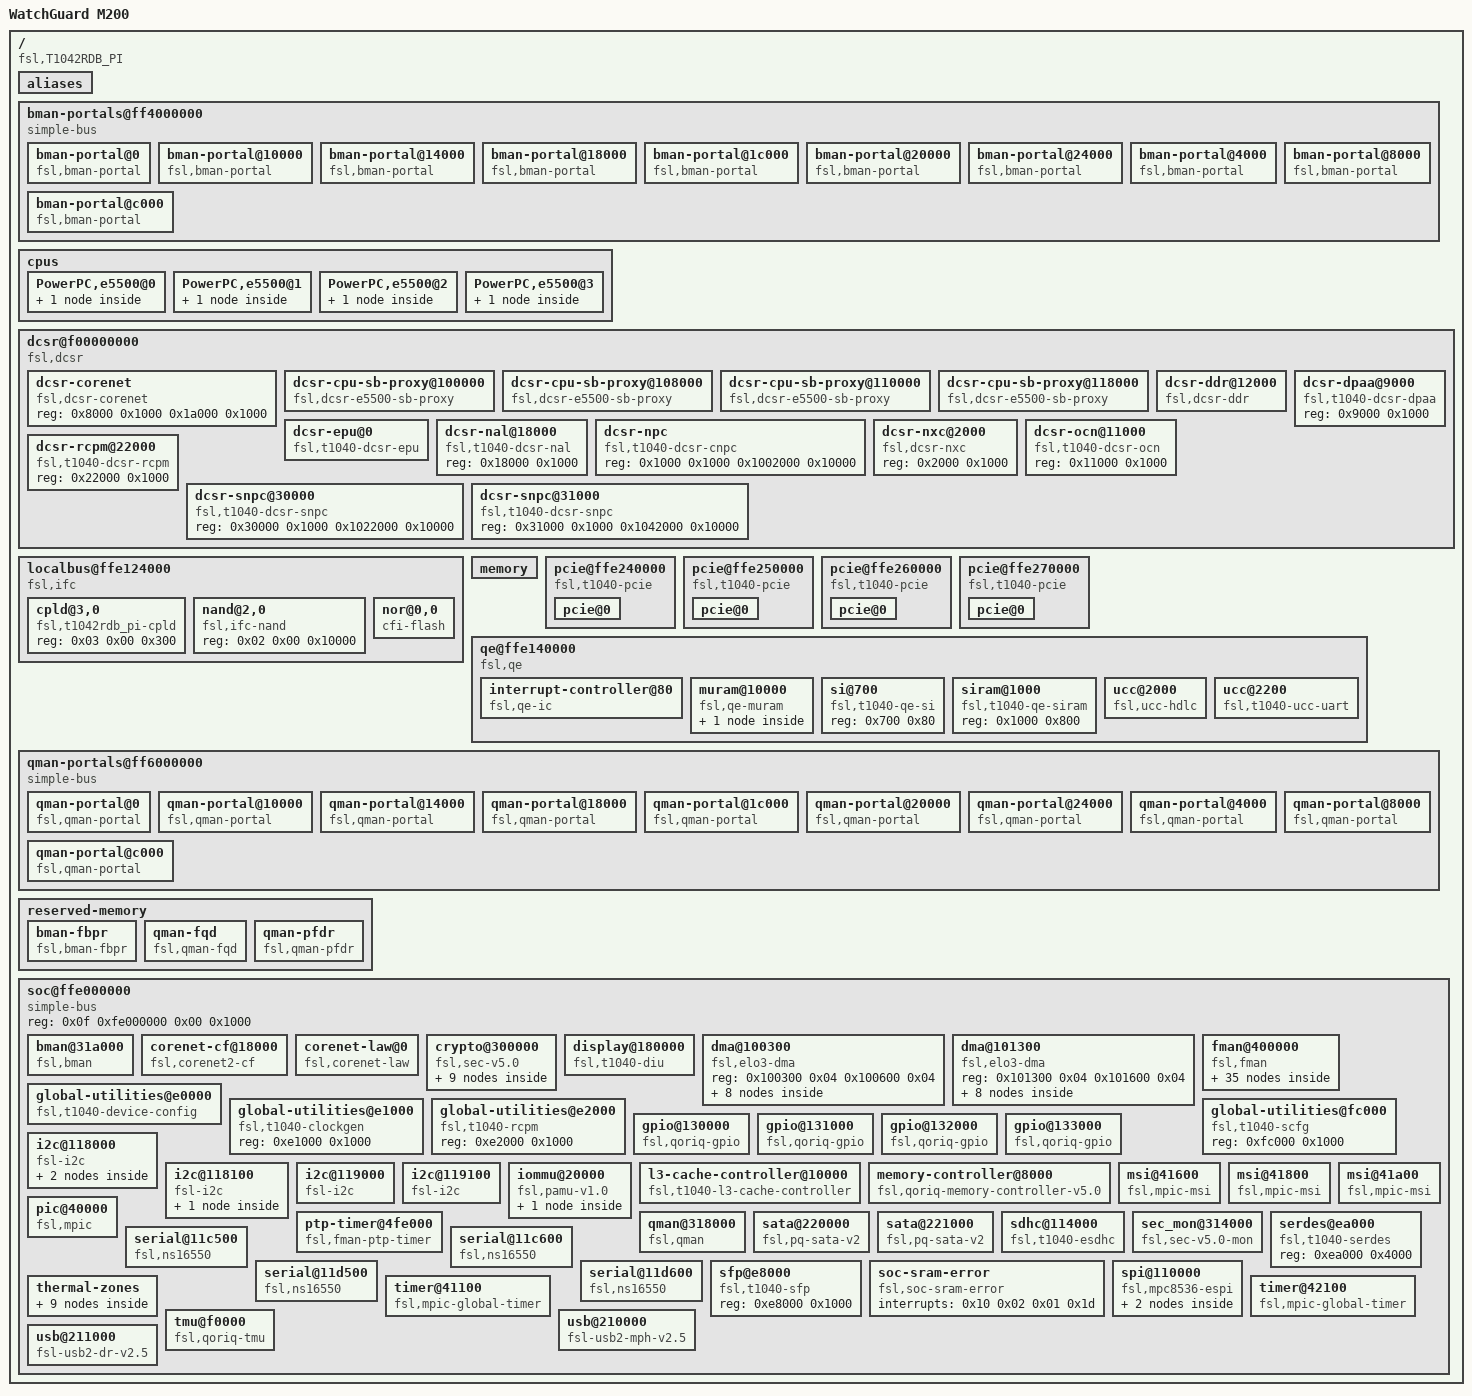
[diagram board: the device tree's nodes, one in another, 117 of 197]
/dts-v1/;

/ {
	#address-cells = <0x02>;
	#size-cells = <0x02>;
	compatible = "fsl,T1042RDB_PI";
	interrupt-parent = <0x01>;
	model = "WatchGuard M200";

	aliases {
		ccsr = "/soc@ffe000000";
		crypto = "/soc@ffe000000/crypto@300000";
		dcsr = "/dcsr@f00000000";
		ethernet0 = "/soc@ffe000000/fman@400000/ethernet@e0000";
		ethernet1 = "/soc@ffe000000/fman@400000/ethernet@e2000";
		ethernet2 = "/soc@ffe000000/fman@400000/ethernet@e4000";
		ethernet3 = "/soc@ffe000000/fman@400000/ethernet@e6000";
		ethernet4 = "/soc@ffe000000/fman@400000/ethernet@e8000";
		fman0 = "/soc@ffe000000/fman@400000";
		pci0 = "/pcie@ffe240000";
		pci1 = "/pcie@ffe250000";
		pci2 = "/pcie@ffe260000";
		pci3 = "/pcie@ffe270000";
		phy_rgmii_0 = "/soc@ffe000000/fman@400000/mdio@fc000/ethernet-phy@1";
		phy_rgmii_1 = "/soc@ffe000000/fman@400000/mdio@fc000/ethernet-phy@2";
		phy_sgmii_2 = "/soc@ffe000000/fman@400000/mdio@fc000/ethernet-phy@3";
		sdhc = "/soc@ffe000000/sdhc@114000";
		serial0 = "/soc@ffe000000/serial@11c500";
		serial1 = "/soc@ffe000000/serial@11c600";
		serial2 = "/soc@ffe000000/serial@11d500";
		serial3 = "/soc@ffe000000/serial@11d600";
		usb0 = "/soc@ffe000000/usb@210000";
		usb1 = "/soc@ffe000000/usb@211000";
	};

	bman-portals@ff4000000 {
		#address-cells = <0x01>;
		#size-cells = <0x01>;
		compatible = "simple-bus";
		phandle = <0x26>;
		ranges = <0x00 0x0f 0xf4000000 0x2000000>;

		bman-portal@0 {
			compatible = "fsl,bman-portal";
			interrupts = <0x69 0x02 0x00 0x00>;
			reg = <0x00 0x4000 0x1000000 0x1000>;
		};

		bman-portal@10000 {
			compatible = "fsl,bman-portal";
			interrupts = <0x71 0x02 0x00 0x00>;
			reg = <0x10000 0x4000 0x1004000 0x1000>;
		};

		bman-portal@14000 {
			compatible = "fsl,bman-portal";
			interrupts = <0x73 0x02 0x00 0x00>;
			reg = <0x14000 0x4000 0x1005000 0x1000>;
		};

		bman-portal@18000 {
			compatible = "fsl,bman-portal";
			interrupts = <0x75 0x02 0x00 0x00>;
			reg = <0x18000 0x4000 0x1006000 0x1000>;
		};

		bman-portal@1c000 {
			compatible = "fsl,bman-portal";
			interrupts = <0x77 0x02 0x00 0x00>;
			reg = <0x1c000 0x4000 0x1007000 0x1000>;
		};

		bman-portal@20000 {
			compatible = "fsl,bman-portal";
			interrupts = <0x79 0x02 0x00 0x00>;
			reg = <0x20000 0x4000 0x1008000 0x1000>;
		};

		bman-portal@24000 {
			compatible = "fsl,bman-portal";
			interrupts = <0x7b 0x02 0x00 0x00>;
			reg = <0x24000 0x4000 0x1009000 0x1000>;
		};

		bman-portal@4000 {
			compatible = "fsl,bman-portal";
			interrupts = <0x6b 0x02 0x00 0x00>;
			reg = <0x4000 0x4000 0x1001000 0x1000>;
		};

		bman-portal@8000 {
			compatible = "fsl,bman-portal";
			interrupts = <0x6d 0x02 0x00 0x00>;
			reg = <0x8000 0x4000 0x1002000 0x1000>;
		};

		bman-portal@c000 {
			compatible = "fsl,bman-portal";
			interrupts = <0x6f 0x02 0x00 0x00>;
			reg = <0xc000 0x4000 0x1003000 0x1000>;
		};
	};

	cpus {
		#address-cells = <0x01>;
		#size-cells = <0x00>;
		fsl,eref-deo;
		mmu-type = "power-embedded";
		power-isa-64;
		power-isa-atb;
		power-isa-b;
		power-isa-cs;
		power-isa-ds;
		power-isa-e;
		power-isa-e.ed;
		power-isa-e.hv;
		power-isa-e.le;
		power-isa-e.pc;
		power-isa-e.pd;
		power-isa-e.pm;
		power-isa-ecl;
		power-isa-exp;
		power-isa-fp;
		power-isa-fp.r;
		power-isa-mmc;
		power-isa-scpm;
		power-isa-version = "2.06";
		power-isa-wt;

		PowerPC,e5500@0 {
			#cooling-cells = <0x02>;
			clocks = <0x02 0x01 0x00>;
			device_type = "cpu";
			next-level-cache = <0x03>;
			phandle = <0x09>;
			reg = <0x00>;

			l2-cache {
				next-level-cache = <0x04>;
				phandle = <0x03>;
			};
		};

		PowerPC,e5500@1 {
			#cooling-cells = <0x02>;
			clocks = <0x02 0x01 0x01>;
			device_type = "cpu";
			next-level-cache = <0x05>;
			phandle = <0x0a>;
			reg = <0x01>;

			l2-cache {
				next-level-cache = <0x04>;
				phandle = <0x05>;
			};
		};

		PowerPC,e5500@2 {
			#cooling-cells = <0x02>;
			clocks = <0x02 0x01 0x02>;
			device_type = "cpu";
			next-level-cache = <0x06>;
			phandle = <0x0b>;
			reg = <0x02>;

			l2-cache {
				next-level-cache = <0x04>;
				phandle = <0x06>;
			};
		};

		PowerPC,e5500@3 {
			#cooling-cells = <0x02>;
			clocks = <0x02 0x01 0x03>;
			device_type = "cpu";
			next-level-cache = <0x07>;
			phandle = <0x0c>;
			reg = <0x03>;

			l2-cache {
				next-level-cache = <0x04>;
				phandle = <0x07>;
			};
		};
	};

	dcsr@f00000000 {
		#address-cells = <0x01>;
		#size-cells = <0x01>;
		compatible = "fsl,dcsr\0simple-bus";
		ranges = <0x00 0x0f 0x00 0x1072000>;

		dcsr-corenet {
			compatible = "fsl,dcsr-corenet";
			reg = <0x8000 0x1000 0x1a000 0x1000>;
		};

		dcsr-cpu-sb-proxy@100000 {
			compatible = "fsl,dcsr-e5500-sb-proxy\0fsl,dcsr-cpu-sb-proxy";
			cpu-handle = <0x09>;
			reg = <0x100000 0x1000 0x101000 0x1000>;
		};

		dcsr-cpu-sb-proxy@108000 {
			compatible = "fsl,dcsr-e5500-sb-proxy\0fsl,dcsr-cpu-sb-proxy";
			cpu-handle = <0x0a>;
			reg = <0x108000 0x1000 0x109000 0x1000>;
		};

		dcsr-cpu-sb-proxy@110000 {
			compatible = "fsl,dcsr-e5500-sb-proxy\0fsl,dcsr-cpu-sb-proxy";
			cpu-handle = <0x0b>;
			reg = <0x110000 0x1000 0x111000 0x1000>;
		};

		dcsr-cpu-sb-proxy@118000 {
			compatible = "fsl,dcsr-e5500-sb-proxy\0fsl,dcsr-cpu-sb-proxy";
			cpu-handle = <0x0c>;
			reg = <0x118000 0x1000 0x119000 0x1000>;
		};

		dcsr-ddr@12000 {
			compatible = "fsl,dcsr-ddr";
			dev-handle = <0x08>;
			reg = <0x12000 0x1000>;
		};

		dcsr-dpaa@9000 {
			compatible = "fsl,t1040-dcsr-dpaa\0fsl,dcsr-dpaa";
			reg = <0x9000 0x1000>;
		};

		dcsr-epu@0 {
			compatible = "fsl,t1040-dcsr-epu\0fsl,dcsr-epu";
			interrupts = <0x34 0x02 0x00 0x00 0x54 0x02 0x00 0x00 0x55 0x02 0x00 0x00>;
			reg = <0x00 0x1000>;
		};

		dcsr-nal@18000 {
			compatible = "fsl,t1040-dcsr-nal\0fsl,dcsr-nal";
			reg = <0x18000 0x1000>;
		};

		dcsr-npc {
			compatible = "fsl,t1040-dcsr-cnpc\0fsl,dcsr-cnpc";
			reg = <0x1000 0x1000 0x1002000 0x10000>;
		};

		dcsr-nxc@2000 {
			compatible = "fsl,dcsr-nxc";
			reg = <0x2000 0x1000>;
		};

		dcsr-ocn@11000 {
			compatible = "fsl,t1040-dcsr-ocn\0fsl,dcsr-ocn";
			reg = <0x11000 0x1000>;
		};

		dcsr-rcpm@22000 {
			compatible = "fsl,t1040-dcsr-rcpm\0fsl,dcsr-rcpm";
			reg = <0x22000 0x1000>;
		};

		dcsr-snpc@30000 {
			compatible = "fsl,t1040-dcsr-snpc\0fsl,dcsr-snpc";
			reg = <0x30000 0x1000 0x1022000 0x10000>;
		};

		dcsr-snpc@31000 {
			compatible = "fsl,t1040-dcsr-snpc\0fsl,dcsr-snpc";
			reg = <0x31000 0x1000 0x1042000 0x10000>;
		};
	};

	localbus@ffe124000 {
		#address-cells = <0x02>;
		#size-cells = <0x01>;
		compatible = "fsl,ifc\0simple-bus";
		interrupts = <0x19 0x02 0x00 0x00>;
		ranges = <0x00 0x00 0x0f 0xe8000000 0x8000000 0x02 0x00 0x0f 0xff800000 0x10000 0x03 0x00 0x0f 0xffdf0000 0x8000>;
		reg = <0x0f 0xfe124000 0x00 0x2000>;

		cpld@3,0 {
			compatible = "fsl,t1042rdb_pi-cpld";
			reg = <0x03 0x00 0x300>;
		};

		nand@2,0 {
			#address-cells = <0x01>;
			#size-cells = <0x01>;
			compatible = "fsl,ifc-nand";
			reg = <0x02 0x00 0x10000>;
		};

		nor@0,0 {
			#address-cells = <0x01>;
			#size-cells = <0x01>;
			bank-width = <0x02>;
			compatible = "cfi-flash";
			device-width = <0x01>;
			reg = <0x00 0x00 0x8000000>;
		};
	};

	memory {
		device_type = "memory";
	};

	pcie@ffe240000 {
		#address-cells = <0x03>;
		#size-cells = <0x02>;
		bus-range = <0x00 0xff>;
		compatible = "fsl,t1040-pcie\0fsl,qoriq-pcie-v2.4\0fsl,qoriq-pcie";
		device_type = "pci";
		fsl,iommu-parent = <0x21>;
		interrupts = <0x14 0x02 0x00 0x00>;
		ranges = <0x2000000 0x00 0xe0000000 0x0c 0x00 0x00 0x10000000 0x1000000 0x00 0x00 0x0f 0xf8000000 0x00 0x10000>;
		reg = <0x0f 0xfe240000 0x00 0x10000>;

		pcie@0 {
			#address-cells = <0x03>;
			#interrupt-cells = <0x01>;
			#size-cells = <0x02>;
			device_type = "pci";
			interrupt-map = <0x00 0x00 0x00 0x01 0x01 0x28 0x01 0x00 0x00 0x00 0x00 0x00 0x02 0x01 0x01 0x01 0x00 0x00 0x00 0x00 0x00 0x03 0x01 0x02 0x01 0x00 0x00 0x00 0x00 0x00 0x04 0x01 0x03 0x01 0x00 0x00>;
			interrupt-map-mask = <0xf800 0x00 0x00 0x07>;
			interrupts = <0x14 0x02 0x00 0x00>;
			ranges = <0x2000000 0x00 0xe0000000 0x2000000 0x00 0xe0000000 0x00 0x10000000 0x1000000 0x00 0x00 0x1000000 0x00 0x00 0x00 0x10000>;
			reg = <0x00 0x00 0x00 0x00 0x00>;
		};
	};

	pcie@ffe250000 {
		#address-cells = <0x03>;
		#size-cells = <0x02>;
		bus-range = <0x00 0xff>;
		compatible = "fsl,t1040-pcie\0fsl,qoriq-pcie-v2.4\0fsl,qoriq-pcie";
		device_type = "pci";
		fsl,iommu-parent = <0x21>;
		interrupts = <0x15 0x02 0x00 0x00>;
		ranges = <0x2000000 0x00 0xe0000000 0x0c 0x10000000 0x00 0x10000000 0x1000000 0x00 0x00 0x0f 0xf8010000 0x00 0x10000>;
		reg = <0x0f 0xfe250000 0x00 0x10000>;

		pcie@0 {
			#address-cells = <0x03>;
			#interrupt-cells = <0x01>;
			#size-cells = <0x02>;
			device_type = "pci";
			interrupt-map = <0x00 0x00 0x00 0x01 0x01 0x29 0x01 0x00 0x00 0x00 0x00 0x00 0x02 0x01 0x05 0x01 0x00 0x00 0x00 0x00 0x00 0x03 0x01 0x06 0x01 0x00 0x00 0x00 0x00 0x00 0x04 0x01 0x07 0x01 0x00 0x00>;
			interrupt-map-mask = <0xf800 0x00 0x00 0x07>;
			interrupts = <0x15 0x02 0x00 0x00>;
			ranges = <0x2000000 0x00 0xe0000000 0x2000000 0x00 0xe0000000 0x00 0x10000000 0x1000000 0x00 0x00 0x1000000 0x00 0x00 0x00 0x10000>;
			reg = <0x00 0x00 0x00 0x00 0x00>;
		};
	};

	pcie@ffe260000 {
		#address-cells = <0x03>;
		#size-cells = <0x02>;
		bus-range = <0x00 0xff>;
		compatible = "fsl,t1040-pcie\0fsl,qoriq-pcie-v2.4\0fsl,qoriq-pcie";
		device_type = "pci";
		fsl,iommu-parent = <0x21>;
		interrupts = <0x16 0x02 0x00 0x00>;
		ranges = <0x2000000 0x00 0xe0000000 0x0c 0x20000000 0x00 0x10000000 0x1000000 0x00 0x00 0x0f 0xf8020000 0x00 0x10000>;
		reg = <0x0f 0xfe260000 0x00 0x10000>;

		pcie@0 {
			#address-cells = <0x03>;
			#interrupt-cells = <0x01>;
			#size-cells = <0x02>;
			device_type = "pci";
			interrupt-map = <0x00 0x00 0x00 0x01 0x01 0x2a 0x01 0x00 0x00 0x00 0x00 0x00 0x02 0x01 0x09 0x01 0x00 0x00 0x00 0x00 0x00 0x03 0x01 0x0a 0x01 0x00 0x00 0x00 0x00 0x00 0x04 0x01 0x0b 0x01 0x00 0x00>;
			interrupt-map-mask = <0xf800 0x00 0x00 0x07>;
			interrupts = <0x16 0x02 0x00 0x00>;
			ranges = <0x2000000 0x00 0xe0000000 0x2000000 0x00 0xe0000000 0x00 0x10000000 0x1000000 0x00 0x00 0x1000000 0x00 0x00 0x00 0x10000>;
			reg = <0x00 0x00 0x00 0x00 0x00>;
		};
	};

	pcie@ffe270000 {
		#address-cells = <0x03>;
		#size-cells = <0x02>;
		bus-range = <0x00 0xff>;
		compatible = "fsl,t1040-pcie\0fsl,qoriq-pcie-v2.4\0fsl,qoriq-pcie";
		device_type = "pci";
		fsl,iommu-parent = <0x21>;
		interrupts = <0x17 0x02 0x00 0x00>;
		ranges = <0x2000000 0x00 0xe0000000 0x0c 0x30000000 0x00 0x10000000 0x1000000 0x00 0x00 0x0f 0xf8030000 0x00 0x10000>;
		reg = <0x0f 0xfe270000 0x00 0x10000>;

		pcie@0 {
			#address-cells = <0x03>;
			#interrupt-cells = <0x01>;
			#size-cells = <0x02>;
			device_type = "pci";
			interrupt-map = <0x00 0x00 0x00 0x01 0x01 0x2b 0x01 0x00 0x00 0x00 0x00 0x00 0x02 0x01 0x00 0x01 0x00 0x00 0x00 0x00 0x00 0x03 0x01 0x04 0x01 0x00 0x00 0x00 0x00 0x00 0x04 0x01 0x08 0x01 0x00 0x00>;
			interrupt-map-mask = <0xf800 0x00 0x00 0x07>;
			interrupts = <0x17 0x02 0x00 0x00>;
			ranges = <0x2000000 0x00 0xe0000000 0x2000000 0x00 0xe0000000 0x00 0x10000000 0x1000000 0x00 0x00 0x1000000 0x00 0x00 0x00 0x10000>;
			reg = <0x00 0x00 0x00 0x00 0x00>;
		};
	};

	qe@ffe140000 {
		#address-cells = <0x01>;
		#size-cells = <0x01>;
		brg-frequency = <0x00>;
		bus-frequency = <0x00>;
		compatible = "fsl,qe";
		device_type = "qe";
		fsl,qe-num-riscs = <0x01>;
		fsl,qe-num-snums = <0x1c>;
		ranges = <0x00 0x0f 0xfe140000 0x40000>;
		reg = <0x0f 0xfe140000 0x00 0x480>;

		interrupt-controller@80 {
			#address-cells = <0x00>;
			#interrupt-cells = <0x01>;
			compatible = "fsl,qe-ic";
			interrupt-controller;
			interrupts = <0x5f 0x02 0x00 0x00 0x5e 0x02 0x00 0x00>;
			phandle = <0x28>;
			reg = <0x80 0x80>;
		};

		muram@10000 {
			#address-cells = <0x01>;
			#size-cells = <0x01>;
			compatible = "fsl,qe-muram\0fsl,cpm-muram";
			ranges = <0x00 0x10000 0x6000>;

			data-only@0 {
				compatible = "fsl,qe-muram-data\0fsl,cpm-muram-data";
				reg = <0x00 0x6000>;
			};
		};

		si@700 {
			compatible = "fsl,t1040-qe-si";
			reg = <0x700 0x80>;
		};

		siram@1000 {
			compatible = "fsl,t1040-qe-siram";
			reg = <0x1000 0x800>;
		};

		ucc@2000 {
			cell-index = <0x01>;
			compatible = "fsl,ucc-hdlc";
			fsl,rx-sync-clock = "rsync_pin";
			fsl,rx-timeslot-mask = <0xfffffffe>;
			fsl,siram-entry-id = <0x00>;
			fsl,tdm-framer-type = "e1";
			fsl,tdm-id = <0x00>;
			fsl,tdm-interface;
			fsl,tx-sync-clock = "tsync_pin";
			fsl,tx-timeslot-mask = <0xfffffffe>;
			interrupt-parent = <0x28>;
			interrupts = <0x20>;
			reg = <0x2000 0x200>;
			rx-clock-name = "clk8";
			tx-clock-name = "clk9";
		};

		ucc@2200 {
			cell-index = <0x03>;
			compatible = "fsl,t1040-ucc-uart";
			interrupt-parent = <0x28>;
			interrupts = <0x22>;
			port-number = <0x00>;
			reg = <0x2200 0x200>;
			rx-clock-name = "brg2";
			tx-clock-name = "brg2";
		};
	};

	qman-portals@ff6000000 {
		#address-cells = <0x01>;
		#size-cells = <0x01>;
		compatible = "simple-bus";
		phandle = <0x23>;
		ranges = <0x00 0x0f 0xf6000000 0x2000000>;

		qman-portal@0 {
			cell-index = <0x00>;
			compatible = "fsl,qman-portal";
			interrupts = <0x68 0x02 0x00 0x00>;
			reg = <0x00 0x4000 0x1000000 0x1000>;
		};

		qman-portal@10000 {
			cell-index = <0x04>;
			compatible = "fsl,qman-portal";
			interrupts = <0x70 0x02 0x00 0x00>;
			reg = <0x10000 0x4000 0x1004000 0x1000>;
		};

		qman-portal@14000 {
			cell-index = <0x05>;
			compatible = "fsl,qman-portal";
			interrupts = <0x72 0x02 0x00 0x00>;
			reg = <0x14000 0x4000 0x1005000 0x1000>;
		};

		qman-portal@18000 {
			cell-index = <0x06>;
			compatible = "fsl,qman-portal";
			interrupts = <0x74 0x02 0x00 0x00>;
			reg = <0x18000 0x4000 0x1006000 0x1000>;
		};

		qman-portal@1c000 {
			cell-index = <0x07>;
			compatible = "fsl,qman-portal";
			interrupts = <0x76 0x02 0x00 0x00>;
			reg = <0x1c000 0x4000 0x1007000 0x1000>;
		};

		qman-portal@20000 {
			cell-index = <0x08>;
			compatible = "fsl,qman-portal";
			interrupts = <0x78 0x02 0x00 0x00>;
			reg = <0x20000 0x4000 0x1008000 0x1000>;
		};

		qman-portal@24000 {
			cell-index = <0x09>;
			compatible = "fsl,qman-portal";
			interrupts = <0x7a 0x02 0x00 0x00>;
			reg = <0x24000 0x4000 0x1009000 0x1000>;
		};

		qman-portal@4000 {
			cell-index = <0x01>;
			compatible = "fsl,qman-portal";
			interrupts = <0x6a 0x02 0x00 0x00>;
			reg = <0x4000 0x4000 0x1001000 0x1000>;
		};

		qman-portal@8000 {
			cell-index = <0x02>;
			compatible = "fsl,qman-portal";
			interrupts = <0x6c 0x02 0x00 0x00>;
			reg = <0x8000 0x4000 0x1002000 0x1000>;
		};

		qman-portal@c000 {
			cell-index = <0x03>;
			compatible = "fsl,qman-portal";
			interrupts = <0x6e 0x02 0x00 0x00>;
			reg = <0xc000 0x4000 0x1003000 0x1000>;
		};
	};

	reserved-memory {
		#address-cells = <0x02>;
		#size-cells = <0x02>;
		ranges;

		bman-fbpr {
			alignment = <0x00 0x1000000>;
			alloc-ranges = <0x00 0x00 0x10000 0x00>;
			compatible = "fsl,bman-fbpr";
			phandle = <0x27>;
			size = <0x00 0x1000000>;
		};

		qman-fqd {
			alignment = <0x00 0x400000>;
			alloc-ranges = <0x00 0x00 0x10000 0x00>;
			compatible = "fsl,qman-fqd";
			phandle = <0x24>;
			size = <0x00 0x400000>;
		};

		qman-pfdr {
			alignment = <0x00 0x2000000>;
			alloc-ranges = <0x00 0x00 0x10000 0x00>;
			compatible = "fsl,qman-pfdr";
			phandle = <0x25>;
			size = <0x00 0x2000000>;
		};
	};

	soc@ffe000000 {
		#address-cells = <0x01>;
		#size-cells = <0x01>;
		compatible = "simple-bus";
		device_type = "soc";
		ranges = <0x00 0x0f 0xfe000000 0x1000000>;
		reg = <0x0f 0xfe000000 0x00 0x1000>;

		bman@31a000 {
			compatible = "fsl,bman";
			fsl,bman-portals = <0x26>;
			interrupts = <0x10 0x02 0x01 0x02>;
			memory-region = <0x27>;
			reg = <0x31a000 0x1000>;
		};

		corenet-cf@18000 {
			compatible = "fsl,corenet2-cf\0fsl,corenet-cf";
			fsl,ccf-num-csdids = <0x20>;
			fsl,ccf-num-snoopids = <0x20>;
			interrupts = <0x10 0x02 0x01 0x1f>;
			reg = <0x18000 0x1000>;
		};

		corenet-law@0 {
			compatible = "fsl,corenet-law";
			fsl,num-laws = <0x10>;
			reg = <0x00 0x1000>;
		};

		crypto@300000 {
			#address-cells = <0x01>;
			#size-cells = <0x01>;
			compatible = "fsl,sec-v5.0\0fsl,sec-v4.0";
			fsl,sec-era = <0x05>;
			interrupts = <0x5c 0x02 0x00 0x00>;
			ranges = <0x00 0x300000 0x10000>;
			reg = <0x300000 0x10000>;

			jr@1000 {
				compatible = "fsl,sec-v5.0-job-ring\0fsl,sec-v4.0-job-ring";
				interrupts = <0x58 0x02 0x00 0x00>;
				reg = <0x1000 0x1000>;
			};

			jr@2000 {
				compatible = "fsl,sec-v5.0-job-ring\0fsl,sec-v4.0-job-ring";
				interrupts = <0x59 0x02 0x00 0x00>;
				reg = <0x2000 0x1000>;
			};

			jr@3000 {
				compatible = "fsl,sec-v5.0-job-ring\0fsl,sec-v4.0-job-ring";
				interrupts = <0x5a 0x02 0x00 0x00>;
				reg = <0x3000 0x1000>;
			};

			jr@4000 {
				compatible = "fsl,sec-v5.0-job-ring\0fsl,sec-v4.0-job-ring";
				interrupts = <0x5b 0x02 0x00 0x00>;
				reg = <0x4000 0x1000>;
			};

			rtic@6000 {
				#address-cells = <0x01>;
				#size-cells = <0x01>;
				compatible = "fsl,sec-v5.0-rtic\0fsl,sec-v4.0-rtic";
				ranges = <0x00 0x6100 0xe00>;
				reg = <0x6000 0x100>;

				rtic-a@0 {
					compatible = "fsl,sec-v5.0-rtic-memory\0fsl,sec-v4.0-rtic-memory";
					reg = <0x00 0x20 0x100 0x80>;
				};

				rtic-b@20 {
					compatible = "fsl,sec-v5.0-rtic-memory\0fsl,sec-v4.0-rtic-memory";
					reg = <0x20 0x20 0x200 0x80>;
				};

				rtic-c@40 {
					compatible = "fsl,sec-v5.0-rtic-memory\0fsl,sec-v4.0-rtic-memory";
					reg = <0x40 0x20 0x300 0x80>;
				};

				rtic-d@60 {
					compatible = "fsl,sec-v5.0-rtic-memory\0fsl,sec-v4.0-rtic-memory";
					reg = <0x60 0x20 0x500 0x80>;
				};
			};
		};

		display@180000 {
			compatible = "fsl,t1040-diu\0fsl,diu";
			interrupts = <0x4a 0x02 0x00 0x00>;
			reg = <0x180000 0x3e8>;
		};

		dma@100300 {
			#address-cells = <0x01>;
			#size-cells = <0x01>;
			compatible = "fsl,elo3-dma";
			ranges = <0x00 0x100100 0x500>;
			reg = <0x100300 0x04 0x100600 0x04>;

			dma-channel@0 {
				compatible = "fsl,eloplus-dma-channel";
				interrupts = <0x1c 0x02 0x00 0x00>;
				reg = <0x00 0x80>;
			};

			dma-channel@100 {
				compatible = "fsl,eloplus-dma-channel";
				interrupts = <0x1e 0x02 0x00 0x00>;
				reg = <0x100 0x80>;
			};

			dma-channel@180 {
				compatible = "fsl,eloplus-dma-channel";
				interrupts = <0x1f 0x02 0x00 0x00>;
				reg = <0x180 0x80>;
			};

			dma-channel@300 {
				compatible = "fsl,eloplus-dma-channel";
				interrupts = <0x4c 0x02 0x00 0x00>;
				reg = <0x300 0x80>;
			};

			dma-channel@380 {
				compatible = "fsl,eloplus-dma-channel";
				interrupts = <0x4d 0x02 0x00 0x00>;
				reg = <0x380 0x80>;
			};

			dma-channel@400 {
				compatible = "fsl,eloplus-dma-channel";
				interrupts = <0x4e 0x02 0x00 0x00>;
				reg = <0x400 0x80>;
			};

			dma-channel@480 {
				compatible = "fsl,eloplus-dma-channel";
				interrupts = <0x4f 0x02 0x00 0x00>;
				reg = <0x480 0x80>;
			};

			dma-channel@80 {
				compatible = "fsl,eloplus-dma-channel";
				interrupts = <0x1d 0x02 0x00 0x00>;
				reg = <0x80 0x80>;
			};
		};

		dma@101300 {
			#address-cells = <0x01>;
			#size-cells = <0x01>;
			compatible = "fsl,elo3-dma";
			ranges = <0x00 0x101100 0x500>;
			reg = <0x101300 0x04 0x101600 0x04>;

			dma-channel@0 {
				compatible = "fsl,eloplus-dma-channel";
				interrupts = <0x20 0x02 0x00 0x00>;
				reg = <0x00 0x80>;
			};

			dma-channel@100 {
				compatible = "fsl,eloplus-dma-channel";
				interrupts = <0x22 0x02 0x00 0x00>;
				reg = <0x100 0x80>;
			};

			dma-channel@180 {
				compatible = "fsl,eloplus-dma-channel";
				interrupts = <0x23 0x02 0x00 0x00>;
				reg = <0x180 0x80>;
			};

			dma-channel@300 {
				compatible = "fsl,eloplus-dma-channel";
				interrupts = <0x50 0x02 0x00 0x00>;
				reg = <0x300 0x80>;
			};

			dma-channel@380 {
				compatible = "fsl,eloplus-dma-channel";
				interrupts = <0x51 0x02 0x00 0x00>;
				reg = <0x380 0x80>;
			};

			dma-channel@400 {
				compatible = "fsl,eloplus-dma-channel";
				interrupts = <0x52 0x02 0x00 0x00>;
				reg = <0x400 0x80>;
			};

			dma-channel@480 {
				compatible = "fsl,eloplus-dma-channel";
				interrupts = <0x53 0x02 0x00 0x00>;
				reg = <0x480 0x80>;
			};

			dma-channel@80 {
				compatible = "fsl,eloplus-dma-channel";
				interrupts = <0x21 0x02 0x00 0x00>;
				reg = <0x80 0x80>;
			};
		};

		fman@400000 {
			#address-cells = <0x01>;
			#size-cells = <0x01>;
			cell-index = <0x00>;
			clock-names = "fmanclk";
			clocks = <0x02 0x03 0x00>;
			compatible = "fsl,fman";
			fsl,qman-channel-range = <0x800 0x10>;
			interrupts = <0x60 0x02 0x00 0x00 0x10 0x02 0x01 0x01>;
			ptimer-handle = <0x0d>;
			ranges = <0x00 0x400000 0xfe000>;
			reg = <0x400000 0xfe000>;

			ethernet@e0000 {
				cell-index = <0x00>;
				compatible = "fsl,fman-memac";
				fsl,fman-ports = <0x16 0x17>;
				pcsphy-handle = <0x18>;
				ptp-timer = <0x0d>;
				reg = <0xe0000 0x1000>;
				status = "disabled";
			};

			ethernet@e2000 {
				cell-index = <0x01>;
				compatible = "fsl,fman-memac";
				fsl,fman-ports = <0x19 0x1a>;
				pcsphy-handle = <0x1b>;
				ptp-timer = <0x0d>;
				reg = <0xe2000 0x1000>;
				status = "disabled";
			};

			ethernet@e4000 {
				cell-index = <0x02>;
				compatible = "fsl,fman-memac";
				fsl,fman-ports = <0x1c 0x1d>;
				pcsphy-handle = <0x1e>;
				ptp-timer = <0x0d>;
				reg = <0xe4000 0x1000>;
				status = "disabled";
			};

			ethernet@e6000 {
				cell-index = <0x03>;
				compatible = "fsl,fman-memac";
				fsl,fman-ports = <0x0f 0x10>;
				pcsphy-handle = <0x11>;
				phy-connection-type = "rgmii";
				phy-handle = <0x0e>;
				ptp-timer = <0x0d>;
				reg = <0xe6000 0x1000>;
			};

			ethernet@e8000 {
				cell-index = <0x04>;
				compatible = "fsl,fman-memac";
				fsl,fman-ports = <0x13 0x14>;
				pcsphy-handle = <0x15>;
				phy-connection-type = "rgmii";
				phy-handle = <0x12>;
				ptp-timer = <0x0d>;
				reg = <0xe8000 0x1000>;
			};

			mdio@e1000 {
				#address-cells = <0x01>;
				#size-cells = <0x00>;
				compatible = "fsl,fman-memac-mdio\0fsl,fman-xmdio";
				fsl,erratum-a011043;
				reg = <0xe1000 0x1000>;

				ethernet-phy@0 {
					phandle = <0x18>;
					reg = <0x00>;
				};
			};

			mdio@e3000 {
				#address-cells = <0x01>;
				#size-cells = <0x00>;
				compatible = "fsl,fman-memac-mdio\0fsl,fman-xmdio";
				fsl,erratum-a011043;
				reg = <0xe3000 0x1000>;

				ethernet-phy@0 {
					phandle = <0x1b>;
					reg = <0x00>;
				};
			};

			mdio@e5000 {
				#address-cells = <0x01>;
				#size-cells = <0x00>;
				compatible = "fsl,fman-memac-mdio\0fsl,fman-xmdio";
				fsl,erratum-a011043;
				reg = <0xe5000 0x1000>;

				ethernet-phy@0 {
					phandle = <0x1e>;
					reg = <0x00>;
				};
			};

			mdio@e7000 {
				#address-cells = <0x01>;
				#size-cells = <0x00>;
				compatible = "fsl,fman-memac-mdio\0fsl,fman-xmdio";
				fsl,erratum-a011043;
				reg = <0xe7000 0x1000>;

				ethernet-phy@0 {
					phandle = <0x11>;
					reg = <0x00>;
				};
			};

			mdio@e9000 {
				#address-cells = <0x01>;
				#size-cells = <0x00>;
				compatible = "fsl,fman-memac-mdio\0fsl,fman-xmdio";
				fsl,erratum-a011043;
				reg = <0xe9000 0x1000>;

				ethernet-phy@0 {
					phandle = <0x15>;
					reg = <0x00>;
				};
			};

			mdio@fc000 {
				#address-cells = <0x01>;
				#size-cells = <0x00>;
				compatible = "fsl,fman-memac-mdio\0fsl,fman-xmdio";
				interrupts = <0x64 0x01 0x00 0x00>;
				reg = <0xfc000 0x1000>;

				ethernet-phy@1 {
					phandle = <0x0e>;
					reg = <0x01>;
				};

				ethernet-phy@2 {
					phandle = <0x12>;
					reg = <0x02>;
				};

				ethernet-phy@3 {
					reg = <0x03>;
				};
			};

			mdio@fd000 {
				#address-cells = <0x01>;
				#size-cells = <0x00>;
				compatible = "fsl,fman-memac-mdio\0fsl,fman-xmdio";
				reg = <0xfd000 0x1000>;
				status = "disabled";
			};

			muram@0 {
				compatible = "fsl,fman-muram";
				reg = <0x00 0x30000>;
			};

			port@82000 {
				cell-index = <0x02>;
				compatible = "fsl,fman-v3-port-oh";
				reg = <0x82000 0x1000>;
			};

			port@83000 {
				cell-index = <0x03>;
				compatible = "fsl,fman-v3-port-oh";
				reg = <0x83000 0x1000>;
			};

			port@84000 {
				cell-index = <0x04>;
				compatible = "fsl,fman-v3-port-oh";
				reg = <0x84000 0x1000>;
			};

			port@85000 {
				cell-index = <0x05>;
				compatible = "fsl,fman-v3-port-oh";
				reg = <0x85000 0x1000>;
			};

			port@88000 {
				cell-index = <0x08>;
				compatible = "fsl,fman-v3-port-rx";
				phandle = <0x16>;
				reg = <0x88000 0x1000>;
			};

			port@89000 {
				cell-index = <0x09>;
				compatible = "fsl,fman-v3-port-rx";
				phandle = <0x19>;
				reg = <0x89000 0x1000>;
			};

			port@8a000 {
				cell-index = <0x0a>;
				compatible = "fsl,fman-v3-port-rx";
				phandle = <0x1c>;
				reg = <0x8a000 0x1000>;
			};

			port@8b000 {
				cell-index = <0x0b>;
				compatible = "fsl,fman-v3-port-rx";
				phandle = <0x0f>;
				reg = <0x8b000 0x1000>;
			};

			port@8c000 {
				cell-index = <0x0c>;
				compatible = "fsl,fman-v3-port-rx";
				phandle = <0x13>;
				reg = <0x8c000 0x1000>;
			};

			port@a8000 {
				cell-index = <0x28>;
				compatible = "fsl,fman-v3-port-tx";
				phandle = <0x17>;
				reg = <0xa8000 0x1000>;
			};

			port@a9000 {
				cell-index = <0x29>;
				compatible = "fsl,fman-v3-port-tx";
				phandle = <0x1a>;
				reg = <0xa9000 0x1000>;
			};

			port@aa000 {
				cell-index = <0x2a>;
				compatible = "fsl,fman-v3-port-tx";
				phandle = <0x1d>;
				reg = <0xaa000 0x1000>;
			};

			port@ab000 {
				cell-index = <0x2b>;
				compatible = "fsl,fman-v3-port-tx";
				phandle = <0x10>;
				reg = <0xab000 0x1000>;
			};

			port@ac000 {
				cell-index = <0x2c>;
				compatible = "fsl,fman-v3-port-tx";
				phandle = <0x14>;
				reg = <0xac000 0x1000>;
			};
		};

		global-utilities@e0000 {
			compatible = "fsl,t1040-device-config\0fsl,qoriq-device-config-2.0";
			fsl,has-rstcr;
			fsl,liodn-bits = <0x0c>;
			phandle = <0x22>;
			reg = <0xe0000 0xe00>;
		};

		global-utilities@e1000 {
			#clock-cells = <0x02>;
			compatible = "fsl,t1040-clockgen\0fsl,qoriq-clockgen-2.0";
			phandle = <0x02>;
			reg = <0xe1000 0x1000>;
		};

		global-utilities@e2000 {
			compatible = "fsl,t1040-rcpm\0fsl,qoriq-rcpm-2.1";
			reg = <0xe2000 0x1000>;
		};

		global-utilities@fc000 {
			compatible = "fsl,t1040-scfg";
			reg = <0xfc000 0x1000>;
		};

		gpio@130000 {
			#gpio-cells = <0x02>;
			compatible = "fsl,qoriq-gpio";
			gpio-controller;
			interrupts = <0x37 0x02 0x00 0x00>;
			reg = <0x130000 0x1000>;
		};

		gpio@131000 {
			#gpio-cells = <0x02>;
			compatible = "fsl,qoriq-gpio";
			gpio-controller;
			interrupts = <0x36 0x02 0x00 0x00>;
			reg = <0x131000 0x1000>;
		};

		gpio@132000 {
			#gpio-cells = <0x02>;
			compatible = "fsl,qoriq-gpio";
			gpio-controller;
			interrupts = <0x56 0x02 0x00 0x00>;
			reg = <0x132000 0x1000>;
		};

		gpio@133000 {
			#gpio-cells = <0x02>;
			compatible = "fsl,qoriq-gpio";
			gpio-controller;
			interrupts = <0x57 0x02 0x00 0x00>;
			reg = <0x133000 0x1000>;
		};

		i2c@118000 {
			#address-cells = <0x01>;
			#size-cells = <0x00>;
			cell-index = <0x00>;
			compatible = "fsl-i2c";
			dfsrr;
			interrupts = <0x26 0x02 0x00 0x00>;
			reg = <0x118000 0x100>;

			adt7461@4c {
				compatible = "adi,adt7461";
				reg = <0x4c>;
			};

			rtc@68 {
				compatible = "dallas,ds1337";
				interrupts = <0x02 0x01 0x00 0x00>;
				reg = <0x68>;
			};
		};

		i2c@118100 {
			#address-cells = <0x01>;
			#size-cells = <0x00>;
			cell-index = <0x01>;
			compatible = "fsl-i2c";
			dfsrr;
			interrupts = <0x26 0x02 0x00 0x00>;
			reg = <0x118100 0x100>;

			pca9546@77 {
				#address-cells = <0x01>;
				#size-cells = <0x00>;
				compatible = "nxp,pca9546";
				reg = <0x77>;
			};
		};

		i2c@119000 {
			#address-cells = <0x01>;
			#size-cells = <0x00>;
			cell-index = <0x02>;
			compatible = "fsl-i2c";
			dfsrr;
			interrupts = <0x27 0x02 0x00 0x00>;
			reg = <0x119000 0x100>;
		};

		i2c@119100 {
			#address-cells = <0x01>;
			#size-cells = <0x00>;
			cell-index = <0x03>;
			compatible = "fsl-i2c";
			dfsrr;
			interrupts = <0x27 0x02 0x00 0x00>;
			reg = <0x119100 0x100>;
		};

		iommu@20000 {
			#address-cells = <0x01>;
			#size-cells = <0x01>;
			compatible = "fsl,pamu-v1.0\0fsl,pamu";
			interrupts = <0x18 0x02 0x00 0x00 0x10 0x02 0x01 0x1e>;
			ranges = <0x00 0x20000 0x1000>;
			reg = <0x20000 0x1000>;

			pamu@0 {
				fsl,primary-cache-geometry = <0x80 0x01>;
				fsl,secondary-cache-geometry = <0x10 0x02>;
				phandle = <0x21>;
				reg = <0x00 0x1000>;
			};
		};

		l3-cache-controller@10000 {
			compatible = "fsl,t1040-l3-cache-controller\0cache";
			interrupts = <0x10 0x02 0x01 0x1b>;
			phandle = <0x04>;
			reg = <0x10000 0x1000>;
		};

		memory-controller@8000 {
			compatible = "fsl,qoriq-memory-controller-v5.0\0fsl,qoriq-memory-controller";
			interrupts = <0x10 0x02 0x01 0x17>;
			phandle = <0x08>;
			reg = <0x8000 0x1000>;
		};

		msi@41600 {
			compatible = "fsl,mpic-msi";
			interrupts = <0xe0 0x00 0x00 0x00 0xe1 0x00 0x00 0x00 0xe2 0x00 0x00 0x00 0xe3 0x00 0x00 0x00 0xe4 0x00 0x00 0x00 0xe5 0x00 0x00 0x00 0xe6 0x00 0x00 0x00 0xe7 0x00 0x00 0x00>;
			msi-available-ranges = <0x00 0x100>;
			reg = <0x41600 0x200 0x44140 0x04>;
		};

		msi@41800 {
			compatible = "fsl,mpic-msi";
			interrupts = <0xe8 0x00 0x00 0x00 0xe9 0x00 0x00 0x00 0xea 0x00 0x00 0x00 0xeb 0x00 0x00 0x00 0xec 0x00 0x00 0x00 0xed 0x00 0x00 0x00 0xee 0x00 0x00 0x00 0xef 0x00 0x00 0x00>;
			msi-available-ranges = <0x00 0x100>;
			reg = <0x41800 0x200 0x45140 0x04>;
		};

		msi@41a00 {
			compatible = "fsl,mpic-msi";
			interrupts = <0xf0 0x00 0x00 0x00 0xf1 0x00 0x00 0x00 0xf2 0x00 0x00 0x00 0xf3 0x00 0x00 0x00 0xf4 0x00 0x00 0x00 0xf5 0x00 0x00 0x00 0xf6 0x00 0x00 0x00 0xf7 0x00 0x00 0x00>;
			msi-available-ranges = <0x00 0x100>;
			reg = <0x41a00 0x200 0x46140 0x04>;
		};

		pic@40000 {
			#address-cells = <0x00>;
			#interrupt-cells = <0x04>;
			clock-frequency = <0x00>;
			compatible = "fsl,mpic\0chrp,open-pic";
			device_type = "open-pic";
			interrupt-controller;
			phandle = <0x01>;
			reg = <0x40000 0x40000>;
		};

		ptp-timer@4fe000 {
			clocks = <0x02 0x03 0x00>;
			compatible = "fsl,fman-ptp-timer";
			interrupts = <0x60 0x02 0x00 0x00>;
			phandle = <0x0d>;
			reg = <0x4fe000 0x1000>;
		};

		qman@318000 {
			compatible = "fsl,qman";
			fsl,qman-portals = <0x23>;
			interrupts = <0x10 0x02 0x01 0x03>;
			memory-region = <0x24 0x25>;
			reg = <0x318000 0x2000>;
		};

		sata@220000 {
			compatible = "fsl,pq-sata-v2";
			fsl,iommu-parent = <0x21>;
			fsl,liodn-reg = <0x22 0x550>;
			interrupts = <0x44 0x02 0x00 0x00>;
			reg = <0x220000 0x1000>;
		};

		sata@221000 {
			compatible = "fsl,pq-sata-v2";
			fsl,iommu-parent = <0x21>;
			fsl,liodn-reg = <0x22 0x554>;
			interrupts = <0x45 0x02 0x00 0x00>;
			reg = <0x221000 0x1000>;
		};

		sdhc@114000 {
			clock-frequency = <0x00>;
			compatible = "fsl,t1040-esdhc\0fsl,esdhc";
			fsl,iommu-parent = <0x21>;
			fsl,liodn-reg = <0x22 0x530>;
			interrupts = <0x30 0x02 0x00 0x00>;
			reg = <0x114000 0x1000>;
			sdhci,auto-cmd12;
		};

		sec_mon@314000 {
			compatible = "fsl,sec-v5.0-mon\0fsl,sec-v4.0-mon";
			interrupts = <0x5d 0x02 0x00 0x00>;
			reg = <0x314000 0x1000>;
		};

		serdes@ea000 {
			compatible = "fsl,t1040-serdes";
			reg = <0xea000 0x4000>;
		};

		serial@11c500 {
			cell-index = <0x00>;
			clock-frequency = <0x00>;
			compatible = "fsl,ns16550\0ns16550";
			device_type = "serial";
			interrupts = <0x24 0x02 0x00 0x00>;
			reg = <0x11c500 0x100>;
		};

		serial@11c600 {
			cell-index = <0x01>;
			clock-frequency = <0x00>;
			compatible = "fsl,ns16550\0ns16550";
			device_type = "serial";
			interrupts = <0x24 0x02 0x00 0x00>;
			reg = <0x11c600 0x100>;
		};

		serial@11d500 {
			cell-index = <0x02>;
			clock-frequency = <0x00>;
			compatible = "fsl,ns16550\0ns16550";
			device_type = "serial";
			interrupts = <0x25 0x02 0x00 0x00>;
			reg = <0x11d500 0x100>;
		};

		serial@11d600 {
			cell-index = <0x03>;
			clock-frequency = <0x00>;
			compatible = "fsl,ns16550\0ns16550";
			device_type = "serial";
			interrupts = <0x25 0x02 0x00 0x00>;
			reg = <0x11d600 0x100>;
		};

		sfp@e8000 {
			compatible = "fsl,t1040-sfp";
			reg = <0xe8000 0x1000>;
		};

		soc-sram-error {
			compatible = "fsl,soc-sram-error";
			interrupts = <0x10 0x02 0x01 0x1d>;
		};

		spi@110000 {
			#address-cells = <0x01>;
			#size-cells = <0x00>;
			compatible = "fsl,mpc8536-espi";
			fsl,espi-num-chipselects = <0x04>;
			interrupts = <0x35 0x02 0x00 0x00>;
			reg = <0x110000 0x1000>;

			flash@0 {
				#address-cells = <0x01>;
				#size-cells = <0x01>;
				compatible = "micron,n25q512ax3\0jedec,spi-nor";
				reg = <0x00>;
				spi-max-frequency = <0x989680>;
			};

			slic@3 {
				compatible = "maxim,ds26522";
				reg = <0x03>;
				spi-max-frequency = <0x1e8480>;
			};
		};

		thermal-zones {

			cpu-thermal {
				polling-delay = <0x1388>;
				polling-delay-passive = <0x3e8>;
				thermal-sensors = <0x1f 0x02>;

				cooling-maps {

					map0 {
						cooling-device = <0x09 0xffffffff 0xffffffff>;
						trip = <0x20>;
					};

					map1 {
						cooling-device = <0x0a 0xffffffff 0xffffffff>;
						trip = <0x20>;
					};

					map2 {
						cooling-device = <0x0b 0xffffffff 0xffffffff>;
						trip = <0x20>;
					};

					map3 {
						cooling-device = <0x0c 0xffffffff 0xffffffff>;
						trip = <0x20>;
					};
				};

				trips {

					cpu-alert {
						hysteresis = <0x7d0>;
						phandle = <0x20>;
						temperature = <0x14c08>;
						type = "passive";
					};

					cpu-crit {
						hysteresis = <0x7d0>;
						temperature = <0x17318>;
						type = "critical";
					};
				};
			};
		};

		timer@41100 {
			compatible = "fsl,mpic-global-timer";
			interrupts = <0x00 0x00 0x03 0x00 0x01 0x00 0x03 0x00 0x02 0x00 0x03 0x00 0x03 0x00 0x03 0x00>;
			reg = <0x41100 0x100 0x41300 0x04>;
		};

		timer@42100 {
			compatible = "fsl,mpic-global-timer";
			interrupts = <0x04 0x00 0x03 0x00 0x05 0x00 0x03 0x00 0x06 0x00 0x03 0x00 0x07 0x00 0x03 0x00>;
			reg = <0x42100 0x100 0x42300 0x04>;
		};

		tmu@f0000 {
			#thermal-sensor-cells = <0x01>;
			compatible = "fsl,qoriq-tmu";
			fsl,tmu-calibration = <0x00 0x25 0x01 0x28 0x02 0x2d 0x03 0x31 0x04 0x36 0x05 0x3a 0x06 0x40 0x07 0x44 0x08 0x4a 0x09 0x4f 0x0a 0x54 0x10000 0x0d 0x10001 0x13 0x10002 0x19 0x10003 0x1f 0x10004 0x25 0x10005 0x2d 0x10006 0x33 0x10007 0x43 0x10008 0x4b 0x10009 0x53 0x20000 0x10 0x20001 0x17 0x20002 0x1f 0x20003 0x29 0x20004 0x31 0x20005 0x3c 0x20006 0x42 0x20007 0x4d 0x20008 0x56 0x30000 0x12 0x30001 0x1d>;
			fsl,tmu-range = <0xa0000 0x90026 0x8004a 0x1006a>;
			interrupts = <0x12 0x02 0x00 0x00>;
			phandle = <0x1f>;
			reg = <0xf0000 0x1000>;
		};

		usb@210000 {
			#address-cells = <0x01>;
			#size-cells = <0x00>;
			compatible = "fsl-usb2-mph-v2.5\0fsl-usb2-mph";
			fsl,iommu-parent = <0x21>;
			fsl,liodn-reg = <0x22 0x520>;
			interrupts = <0x2c 0x02 0x00 0x00>;
			phy_type = "utmi";
			port0;
			reg = <0x210000 0x1000>;
		};

		usb@211000 {
			#address-cells = <0x01>;
			#size-cells = <0x00>;
			compatible = "fsl-usb2-dr-v2.5\0fsl-usb2-dr";
			dr_mode = "host";
			fsl,iommu-parent = <0x21>;
			fsl,liodn-reg = <0x22 0x524>;
			interrupts = <0x2d 0x02 0x00 0x00>;
			phy_type = "utmi";
			reg = <0x211000 0x1000>;
		};
	};
};
